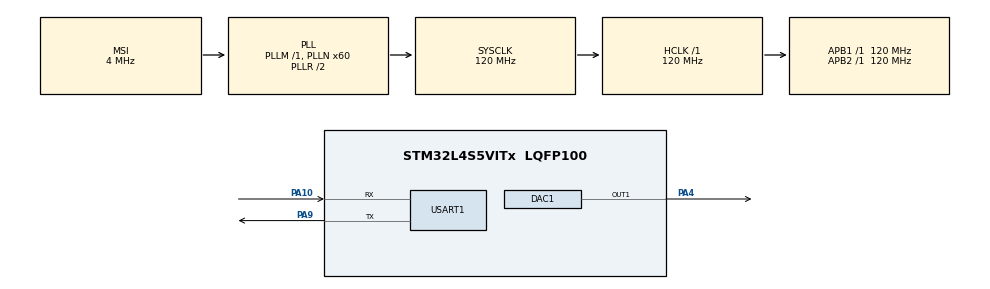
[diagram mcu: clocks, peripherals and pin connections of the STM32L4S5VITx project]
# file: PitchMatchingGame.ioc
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Dma.DAC1_CH1.0.Direction=DMA_MEMORY_TO_PERIPH
Dma.DAC1_CH1.0.EventEnable=DISABLE
Dma.DAC1_CH1.0.Instance=DMA1_Channel1
Dma.DAC1_CH1.0.MemDataAlignment=DMA_MDATAALIGN_BYTE
Dma.DAC1_CH1.0.MemInc=DMA_MINC_ENABLE
Dma.DAC1_CH1.0.Mode=DMA_CIRCULAR
Dma.DAC1_CH1.0.PeriphDataAlignment=DMA_PDATAALIGN_HALFWORD
Dma.DAC1_CH1.0.PeriphInc=DMA_PINC_DISABLE
Dma.DAC1_CH1.0.Polarity=HAL_DMAMUX_REQUEST_GEN_RISING
Dma.DAC1_CH1.0.Priority=DMA_PRIORITY_LOW
Dma.DAC1_CH1.0.RequestNumber=1
Dma.DAC1_CH1.0.SignalID=NONE
Dma.DAC1_CH1.0.SyncEnable=DISABLE
Dma.DAC1_CH1.0.SyncPolarity=HAL_DMAMUX_SYNC_NO_EVENT
Dma.DAC1_CH1.0.SyncRequestNumber=1
Dma.DAC1_CH1.0.SyncSignalID=NONE
Dma.Request0=DAC1_CH1
Mcu.Family=STM32L4
Mcu.Name=STM32L4S5VITx
Mcu.Package=LQFP100
NVIC.DMA1_Channel1_IRQn=true\:0\:0\:false\:false\:true\:false\:true\:true
NVIC.PriorityGroup=NVIC_PRIORITYGROUP_4
NVIC.USART1_IRQn=true\:0\:0\:false\:false\:true\:true\:true\:true
PA10.Mode=Asynchronous
PA10.Signal=USART1_RX
PA4.Signal=COMP_DAC11_group
PA9.Mode=Asynchronous
PA9.Signal=USART1_TX
ProjectManager.HeapSize=0x200
ProjectManager.StackSize=0x400
ProjectManager.TargetToolchain=STM32CubeIDE
RCC.ADCFreq_Value=48000000
RCC.AHBFreq_Value=120000000
RCC.APB1Freq_Value=120000000
RCC.APB1TimFreq_Value=120000000
RCC.APB2Freq_Value=120000000
RCC.APB2TimFreq_Value=120000000
RCC.CortexFreq_Value=120000000
RCC.HCLKFreq_Value=120000000
RCC.HSE_VALUE=8000000
RCC.HSI48_VALUE=48000000
RCC.HSI_VALUE=16000000
RCC.LSE_VALUE=32768
RCC.MSI_VALUE=4000000
RCC.PLLN=60
RCC.PLLSAI1N=24
RCC.SYSCLKFreq_VALUE=120000000
RCC.SYSCLKSource=RCC_SYSCLKSOURCE_PLLCLK
RCC.USBFreq_Value=48000000
RCC.VCOOutputFreq_Value=240000000
SH.COMP_DAC11_group.0=DAC1_OUT1,DAC_OUT1
USART1.VirtualMode-Asynchronous=VM_ASYNC
board=B-L4S5I-IOT01A

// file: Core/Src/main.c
/* USER CODE BEGIN Header */
/**
  ******************************************************************************
  * @file           : main.c
  * @brief          : Main program body
  ******************************************************************************
  * @attention
  *
  * Copyright (c) 2025 STMicroelectronics.
  * All rights reserved.
  *
  * This software is licensed under terms that can be found in the LICENSE file
  * in the root directory of this software component.
  * If no LICENSE file comes with this software, it is provided AS-IS.
  *
  ******************************************************************************
  */
/* USER CODE END Header */
#include "main.h"

/* USER CODE BEGIN PD */
#define DAC_MAX_BUFFER_SIZE 30
/* USER CODE END PD */

DAC_HandleTypeDef hdac1;
DMA_HandleTypeDef hdma_dac1_ch1;

UART_HandleTypeDef huart1;

/* USER CODE BEGIN PV */
#define RECORD_LEN	65000	// samples for 65k/44.1khz = 1.47s
float32_t sine_value;
uint8_t dacBuffer[RECORD_LEN];  // DAC reads here (8-bit samples, since we read a byte from memory)
int32_t dfsdmBuffer[RECORD_LEN]; // DFSDM writes here (32-bit samples)

// Global array for DMA:
volatile uint8_t sine_wave_array[DAC_MAX_BUFFER_SIZE];

/* USER CODE END PV */

void SystemClock_Config(void);
static void MX_GPIO_Init(void);
static void MX_DMA_Init(void);
static void MX_DAC1_Init(void);
static void MX_USART1_UART_Init(void);

/* USER CODE BEGIN 0 */
void play_sound(void){
	//generate sine wave:
	for (int i = 0; i < DAC_MAX_BUFFER_SIZE; i++) {
	  angle = 2.0f * 3.1415926535f * i / DAC_MAX_BUFFER_SIZE;
	  sine_value = arm_sin_f32(angle);
	  sine_wave_array[i] = (uint8_t)(42.5f * sine_value + 127.5f);
	}
	// Start DAC in DMA mode for the sine wave:
	HAL_DAC_Start_DMA(&hdac1, DAC_CHANNEL_1, (uint32_t*)sine_wave_array, 100, DAC_ALIGN_8B_R); //set DAC to read bytes from memory...
}

/* USER CODE END 0 */

int main(void)
{

  /* MCU Configuration--------------------------------------------------------*/

  /* Reset of all peripherals, Initializes the Flash interface and the Systick. */
  HAL_Init();

  /* Configure the system clock */
  SystemClock_Config();

  /* Initialize all configured peripherals */
  MX_GPIO_Init();
  MX_DMA_Init();
  MX_DAC1_Init();
  MX_USART1_UART_Init();

  /* Infinite loop */
  /* USER CODE BEGIN WHILE */
  while (1)
  {
	play_sound();
	HAL_Delay(300);
	HAL_DAC_Stop_DMA(&hdac1, DAC_CHANNEL_1);
    /* USER CODE END WHILE */

  }
}

void SystemClock_Config(void)
{
  RCC_OscInitTypeDef RCC_OscInitStruct = {0};
  RCC_ClkInitTypeDef RCC_ClkInitStruct = {0};

  /** Configure the main internal regulator output voltage
  */
  if (HAL_PWREx_ControlVoltageScaling(PWR_REGULATOR_VOLTAGE_SCALE1_BOOST) != HAL_OK)
  {
    Error_Handler();
  }

  /** Initializes the RCC Oscillators according to the specified parameters
  * in the RCC_OscInitTypeDef structure.
  */
  RCC_OscInitStruct.OscillatorType = RCC_OSCILLATORTYPE_MSI;
  RCC_OscInitStruct.MSIState = RCC_MSI_ON;
  RCC_OscInitStruct.MSICalibrationValue = 0;
  RCC_OscInitStruct.MSIClockRange = RCC_MSIRANGE_6;
  RCC_OscInitStruct.PLL.PLLState = RCC_PLL_ON;
  RCC_OscInitStruct.PLL.PLLSource = RCC_PLLSOURCE_MSI;
  RCC_OscInitStruct.PLL.PLLM = 1;
  RCC_OscInitStruct.PLL.PLLN = 60;
  RCC_OscInitStruct.PLL.PLLP = RCC_PLLP_DIV2;
  RCC_OscInitStruct.PLL.PLLQ = RCC_PLLQ_DIV2;
  RCC_OscInitStruct.PLL.PLLR = RCC_PLLR_DIV2;
  if (HAL_RCC_OscConfig(&RCC_OscInitStruct) != HAL_OK)
  {
    Error_Handler();
  }

  /** Initializes the CPU, AHB and APB buses clocks
  */
  RCC_ClkInitStruct.ClockType = RCC_CLOCKTYPE_HCLK|RCC_CLOCKTYPE_SYSCLK
                              |RCC_CLOCKTYPE_PCLK1|RCC_CLOCKTYPE_PCLK2;
  RCC_ClkInitStruct.SYSCLKSource = RCC_SYSCLKSOURCE_PLLCLK;
  RCC_ClkInitStruct.AHBCLKDivider = RCC_SYSCLK_DIV1;
  RCC_ClkInitStruct.APB1CLKDivider = RCC_HCLK_DIV1;
  RCC_ClkInitStruct.APB2CLKDivider = RCC_HCLK_DIV1;

  if (HAL_RCC_ClockConfig(&RCC_ClkInitStruct, FLASH_LATENCY_5) != HAL_OK)
  {
    Error_Handler();
  }
}

static void MX_DAC1_Init(void)
{

  DAC_ChannelConfTypeDef sConfig = {0};

  /** DAC Initialization
  */
  hdac1.Instance = DAC1;
  if (HAL_DAC_Init(&hdac1) != HAL_OK)
  {
    Error_Handler();
  }

  /** DAC channel OUT1 config
  */
  sConfig.DAC_SampleAndHold = DAC_SAMPLEANDHOLD_DISABLE;
  sConfig.DAC_Trigger = DAC_TRIGGER_NONE;
  sConfig.DAC_HighFrequency = DAC_HIGH_FREQUENCY_INTERFACE_MODE_ABOVE_80MHZ;
  sConfig.DAC_OutputBuffer = DAC_OUTPUTBUFFER_ENABLE;
  sConfig.DAC_ConnectOnChipPeripheral = DAC_CHIPCONNECT_DISABLE;
  sConfig.DAC_UserTrimming = DAC_TRIMMING_FACTORY;
  if (HAL_DAC_ConfigChannel(&hdac1, &sConfig, DAC_CHANNEL_1) != HAL_OK)
  {
    Error_Handler();
  }

}

static void MX_USART1_UART_Init(void)
{

  huart1.Instance = USART1;
  huart1.Init.BaudRate = 115200;
  huart1.Init.WordLength = UART_WORDLENGTH_8B;
  huart1.Init.StopBits = UART_STOPBITS_1;
  huart1.Init.Parity = UART_PARITY_NONE;
  huart1.Init.Mode = UART_MODE_TX_RX;
  huart1.Init.HwFlowCtl = UART_HWCONTROL_NONE;
  huart1.Init.OverSampling = UART_OVERSAMPLING_16;
  huart1.Init.OneBitSampling = UART_ONE_BIT_SAMPLE_DISABLE;
  huart1.Init.ClockPrescaler = UART_PRESCALER_DIV1;
  huart1.AdvancedInit.AdvFeatureInit = UART_ADVFEATURE_NO_INIT;
  if (HAL_UART_Init(&huart1) != HAL_OK)
  {
    Error_Handler();
  }
  if (HAL_UARTEx_SetTxFifoThreshold(&huart1, UART_TXFIFO_THRESHOLD_1_8) != HAL_OK)
  {
    Error_Handler();
  }
  if (HAL_UARTEx_SetRxFifoThreshold(&huart1, UART_RXFIFO_THRESHOLD_1_8) != HAL_OK)
  {
    Error_Handler();
  }
  if (HAL_UARTEx_DisableFifoMode(&huart1) != HAL_OK)
  {
    Error_Handler();
  }

}

static void MX_DMA_Init(void)
{

  /* DMA controller clock enable */
  __HAL_RCC_DMAMUX1_CLK_ENABLE();
  __HAL_RCC_DMA1_CLK_ENABLE();

  /* DMA interrupt init */
  /* DMA1_Channel1_IRQn interrupt configuration */
  HAL_NVIC_SetPriority(DMA1_Channel1_IRQn, 0, 0);
  HAL_NVIC_EnableIRQ(DMA1_Channel1_IRQn);

}

static void MX_GPIO_Init(void)
{

  /* GPIO Ports Clock Enable */
  __HAL_RCC_GPIOA_CLK_ENABLE();

}

void Error_Handler(void)
{
  __disable_irq();
  while (1)
  {
  }
}
